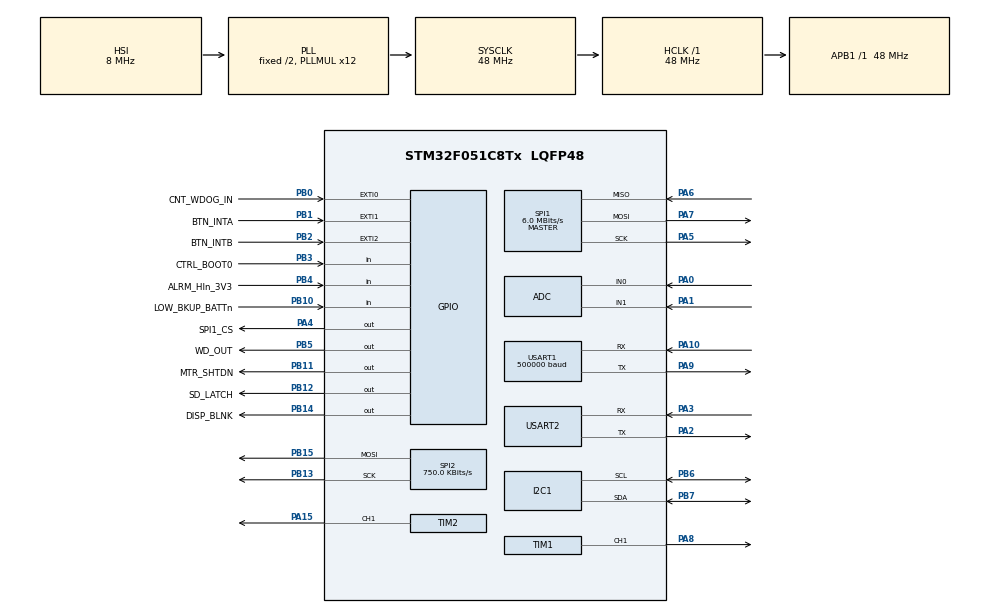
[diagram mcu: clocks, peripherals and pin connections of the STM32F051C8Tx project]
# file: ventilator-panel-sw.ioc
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Dma.Request0=USART1_RX
Dma.Request1=USART1_TX
Dma.USART1_RX.0.Direction=DMA_PERIPH_TO_MEMORY
Dma.USART1_RX.0.Instance=DMA1_Channel3
Dma.USART1_RX.0.MemDataAlignment=DMA_MDATAALIGN_BYTE
Dma.USART1_RX.0.MemInc=DMA_MINC_ENABLE
Dma.USART1_RX.0.Mode=DMA_CIRCULAR
Dma.USART1_RX.0.PeriphDataAlignment=DMA_PDATAALIGN_BYTE
Dma.USART1_RX.0.PeriphInc=DMA_PINC_DISABLE
Dma.USART1_RX.0.Priority=DMA_PRIORITY_VERY_HIGH
Dma.USART1_TX.1.Direction=DMA_MEMORY_TO_PERIPH
Dma.USART1_TX.1.Instance=DMA1_Channel2
Dma.USART1_TX.1.MemDataAlignment=DMA_MDATAALIGN_BYTE
Dma.USART1_TX.1.MemInc=DMA_MINC_ENABLE
Dma.USART1_TX.1.Mode=DMA_NORMAL
Dma.USART1_TX.1.PeriphDataAlignment=DMA_PDATAALIGN_BYTE
Dma.USART1_TX.1.PeriphInc=DMA_PINC_DISABLE
Dma.USART1_TX.1.Priority=DMA_PRIORITY_LOW
I2C1.Analog_Filter=I2C_ANALOGFILTER_ENABLE
I2C1.Timing=0x2000090E
Mcu.Family=STM32F0
Mcu.Name=STM32F051C8Tx
Mcu.Package=LQFP48
NVIC.DMA1_Channel2_3_IRQn=true\:0\:0\:false\:false\:true\:false\:true
NVIC.EXTI0_1_IRQn=true\:0\:0\:false\:false\:true\:true\:true
NVIC.TIM6_DAC_IRQn=true\:0\:0\:false\:false\:true\:true\:true
PA0.Mode=IN0
PA0.Signal=ADC_IN0
PA1.Mode=IN1
PA1.Signal=ADC_IN1
PA10.Mode=Asynchronous
PA10.Signal=USART1_RX
PA13.Mode=Serial_Wire
PA13.Signal=SYS_SWDIO
PA14.Mode=Serial_Wire
PA14.Signal=SYS_SWCLK
PA15.Signal=S_TIM2_CH1_ETR
PA2.Mode=Asynchronous
PA2.Signal=USART2_TX
PA3.Mode=Asynchronous
PA3.Signal=USART2_RX
PA4.GPIO_Label=SPI1_CS
PA4.Signal=GPIO_Output
PA5.Mode=Full_Duplex_Master
PA5.Signal=SPI1_SCK
PA6.Mode=Full_Duplex_Master
PA6.Signal=SPI1_MISO
PA7.Mode=Full_Duplex_Master
PA7.Signal=SPI1_MOSI
PA8.Signal=S_TIM1_CH1
PA9.Mode=Asynchronous
PA9.Signal=USART1_TX
PB0.GPIO_Label=CNT_WDOG_IN
PB0.GPIO_ModeDefaultEXTI=GPIO_MODE_IT_RISING_FALLING
PB0.Signal=GPXTI0
PB1.GPIO_Label=BTN_INTA
PB1.Signal=GPXTI1
PB10.GPIO_Label=LOW_BKUP_BATTn
PB10.Signal=GPIO_Input
PB11.GPIO_Label=MTR_SHTDN
PB11.Signal=GPIO_Output
PB12.GPIO_Label=SD_LATCH
PB12.Signal=GPIO_Output
PB13.Mode=TX_Only_Simplex_Unidirect_Master
PB13.Signal=SPI2_SCK
PB14.GPIO_Label=DISP_BLNK
PB14.PinState=GPIO_PIN_SET
PB14.Signal=GPIO_Output
PB15.Mode=TX_Only_Simplex_Unidirect_Master
PB15.Signal=SPI2_MOSI
PB2.GPIO_Label=BTN_INTB
PB2.Signal=GPXTI2
PB3.GPIO_Label=CTRL_BOOT0
PB3.Signal=GPIO_Input
PB4.GPIO_Label=ALRM_HIn_3V3
PB4.Signal=GPIO_Input
PB5.GPIO_Label=WD_OUT
PB5.Signal=GPIO_Output
PB6.Mode=I2C
PB6.Signal=I2C1_SCL
PB7.Mode=I2C
PB7.Signal=I2C1_SDA
ProjectManager.HeapSize=0x200
ProjectManager.StackSize=0x400
ProjectManager.TargetToolchain=STM32CubeIDE
RCC.AHBFreq_Value=48000000
RCC.APB1Freq_Value=48000000
RCC.APB1TimFreq_Value=48000000
RCC.HCLKFreq_Value=48000000
RCC.PLLMUL=RCC_PLL_MUL12
RCC.SYSCLKFreq_VALUE=48000000
RCC.SYSCLKSource=RCC_SYSCLKSOURCE_PLLCLK
SH.S_TIM1_CH1.0=TIM1_CH1,PWM Generation1 CH1
SH.S_TIM2_CH1_ETR.0=TIM2_CH1,PWM Generation1 CH1
SPI1.BaudRatePrescaler=SPI_BAUDRATEPRESCALER_8
SPI1.CLKPolarity=SPI_POLARITY_LOW
SPI1.CalculateBaudRate=6.0 MBits/s
SPI1.DataSize=SPI_DATASIZE_8BIT
SPI1.Direction=SPI_DIRECTION_2LINES
SPI1.Mode=SPI_MODE_MASTER
SPI1.VirtualType=VM_MASTER
SPI2.BaudRatePrescaler=SPI_BAUDRATEPRESCALER_64
SPI2.CalculateBaudRate=750.0 KBits/s
SPI2.DataSize=SPI_DATASIZE_16BIT
SPI2.Direction=SPI_DIRECTION_2LINES
SPI2.Mode=SPI_MODE_MASTER
SPI2.NSSPMode=SPI_NSS_PULSE_ENABLE
SPI2.VirtualType=VM_MASTER
TIM1.AutoReloadPreload=TIM_AUTORELOAD_PRELOAD_ENABLE
TIM1.Channel-PWM\ Generation1\ CH1=TIM_CHANNEL_1
TIM1.ClockDivision=TIM_CLOCKDIVISION_DIV1
TIM1.Period=17167
TIM1.Prescaler=4
TIM1.Pulse-PWM\ Generation1\ CH1=8584
TIM2.AutoReloadPreload=TIM_AUTORELOAD_PRELOAD_ENABLE
TIM2.Channel-PWM\ Generation1\ CH1=TIM_CHANNEL_1
TIM2.Period=24
TIM2.Prescaler=4
TIM2.Pulse-PWM\ Generation1\ CH1=12
TIM6.AutoReloadPreload=TIM_AUTORELOAD_PRELOAD_ENABLE
TIM6.Period=1000
TIM6.Prescaler=47999
USART1.BaudRate=500000
USART1.VirtualMode-Asynchronous=VM_ASYNC
USART2.VirtualMode-Asynchronous=VM_ASYNC
VP_TIM1_VS_ClockSourceINT.Mode=Internal
VP_TIM2_VS_ClockSourceINT.Mode=Internal
VP_TIM6_VS_ClockSourceINT.Mode=Enable_Timer
board=custom

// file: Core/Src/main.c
/* USER CODE BEGIN Header */
/**
  ******************************************************************************
  * @file           : main.c
  * @brief          : Main program body
  ******************************************************************************
  * @attention
  *
  * <h2><center>&copy; Copyright (c) 2020 STMicroelectronics.
  * All rights reserved.</center></h2>
  *
  * This software component is licensed by ST under BSD 3-Clause license,
  * the "License"; You may not use this file except in compliance with the
  * License. You may obtain a copy of the License at:
  *                        opensource.org/licenses/BSD-3-Clause
  *
  ******************************************************************************
  */
/* USER CODE END Header */

#include "main.h"

/* USER CODE BEGIN Includes */
#include <ventilator/cycle.h>
#include <ventilator/panel.h>
#include <ventilator/types.h>
#define EXTERN // Forces variables to be instantiated
#include <ventilator/panel_public.h>

/* USER CODE END Includes */

ADC_HandleTypeDef hadc;

I2C_HandleTypeDef hi2c1;

SPI_HandleTypeDef hspi1;
SPI_HandleTypeDef hspi2;

TIM_HandleTypeDef htim1;
TIM_HandleTypeDef htim2;
TIM_HandleTypeDef htim6;

UART_HandleTypeDef huart1;
UART_HandleTypeDef huart2;
DMA_HandleTypeDef hdma_usart1_rx;
DMA_HandleTypeDef hdma_usart1_tx;

/* USER CODE BEGIN PV */

// Instantiate public handles by undef'ing EXTERN

volatile FailSafeClockState p_doFail = FAIL_SAFE_CLOCK_UNINITIALIZED; // Needs to be set immediately

/* USER CODE END PV */

void SystemClock_Config(void);
static void MX_GPIO_Init(void);
static void MX_DMA_Init(void);
static void MX_ADC_Init(void);
static void MX_I2C1_Init(void);
static void MX_SPI1_Init(void);
static void MX_SPI2_Init(void);
static void MX_TIM1_Init(void);
static void MX_TIM2_Init(void);
static void MX_TIM6_Init(void);
static void MX_USART1_UART_Init(void);
static void MX_USART2_UART_Init(void);

int main(void)
{

  /* MCU Configuration--------------------------------------------------------*/

  /* Reset of all peripherals, Initializes the Flash interface and the Systick. */
  (void) HAL_Init();

  /* Configure the system clock */
  SystemClock_Config();

  /* Initialize all configured peripherals */
  MX_GPIO_Init();
  MX_DMA_Init();
  MX_ADC_Init();
  MX_I2C1_Init();
  MX_SPI1_Init();
  MX_SPI2_Init();
  MX_TIM1_Init();
  MX_TIM2_Init();
  MX_TIM6_Init();
  MX_USART1_UART_Init();
  MX_USART2_UART_Init();
  /* USER CODE BEGIN 2 */
  HAL_GPIO_WritePin(GPIOB, MTR_SHTDN_Pin, GPIO_PIN_RESET);  //Don't shutdown motor
  panel_init();
  /* USER CODE END 2 */

  /* Infinite loop */
  /* USER CODE BEGIN WHILE */
  //Start the 1Hz timer for debugging
  SW_ASSERT(HAL_TIM_Base_Start_IT(&htim6) == HAL_OK);
  p_doFail = FAIL_SAFE_CLOCK_RUNNING;  // Unleash the fail-safe clock
  while (1)
  {
    /* USER CODE END WHILE */

    /* USER CODE BEGIN 3 */
    cycle();
  }
  /* USER CODE END 3 */
}

void SystemClock_Config(void)
{
  RCC_OscInitTypeDef RCC_OscInitStruct = {0};
  RCC_ClkInitTypeDef RCC_ClkInitStruct = {0};
  RCC_PeriphCLKInitTypeDef PeriphClkInit = {0};

  /** Initializes the CPU, AHB and APB busses clocks
  */
  RCC_OscInitStruct.OscillatorType = RCC_OSCILLATORTYPE_HSI|RCC_OSCILLATORTYPE_HSI14;
  RCC_OscInitStruct.HSIState = RCC_HSI_ON;
  RCC_OscInitStruct.HSI14State = RCC_HSI14_ON;
  RCC_OscInitStruct.HSICalibrationValue = RCC_HSICALIBRATION_DEFAULT;
  RCC_OscInitStruct.HSI14CalibrationValue = 16;
  RCC_OscInitStruct.PLL.PLLState = RCC_PLL_ON;
  RCC_OscInitStruct.PLL.PLLSource = RCC_PLLSOURCE_HSI;
  RCC_OscInitStruct.PLL.PLLMUL = RCC_PLL_MUL12;
  RCC_OscInitStruct.PLL.PREDIV = RCC_PREDIV_DIV1;
  if (HAL_RCC_OscConfig(&RCC_OscInitStruct) != HAL_OK)
  {
    Error_Handler();
  }
  /** Initializes the CPU, AHB and APB busses clocks
  */
  RCC_ClkInitStruct.ClockType = RCC_CLOCKTYPE_HCLK|RCC_CLOCKTYPE_SYSCLK
                              |RCC_CLOCKTYPE_PCLK1;
  RCC_ClkInitStruct.SYSCLKSource = RCC_SYSCLKSOURCE_PLLCLK;
  RCC_ClkInitStruct.AHBCLKDivider = RCC_SYSCLK_DIV1;
  RCC_ClkInitStruct.APB1CLKDivider = RCC_HCLK_DIV1;

  if (HAL_RCC_ClockConfig(&RCC_ClkInitStruct, FLASH_LATENCY_1) != HAL_OK)
  {
    Error_Handler();
  }
  PeriphClkInit.PeriphClockSelection = RCC_PERIPHCLK_USART1|RCC_PERIPHCLK_I2C1;
  PeriphClkInit.Usart1ClockSelection = RCC_USART1CLKSOURCE_PCLK1;
  PeriphClkInit.I2c1ClockSelection = RCC_I2C1CLKSOURCE_HSI;
  if (HAL_RCCEx_PeriphCLKConfig(&PeriphClkInit) != HAL_OK)
  {
    Error_Handler();
  }
}

static void MX_ADC_Init(void)
{

  ADC_ChannelConfTypeDef sConfig = {0};

  /** Configure the global features of the ADC (Clock, Resolution, Data Alignment and number of conversion)
  */
  hadc.Instance = ADC1;
  hadc.Init.ClockPrescaler = ADC_CLOCK_ASYNC_DIV1;
  hadc.Init.Resolution = ADC_RESOLUTION_12B;
  hadc.Init.DataAlign = ADC_DATAALIGN_RIGHT;
  hadc.Init.ScanConvMode = ADC_SCAN_DIRECTION_FORWARD;
  hadc.Init.EOCSelection = ADC_EOC_SINGLE_CONV;
  hadc.Init.LowPowerAutoWait = DISABLE;
  hadc.Init.LowPowerAutoPowerOff = DISABLE;
  hadc.Init.ContinuousConvMode = DISABLE;
  hadc.Init.DiscontinuousConvMode = DISABLE;
  hadc.Init.ExternalTrigConv = ADC_SOFTWARE_START;
  hadc.Init.ExternalTrigConvEdge = ADC_EXTERNALTRIGCONVEDGE_NONE;
  hadc.Init.DMAContinuousRequests = DISABLE;
  hadc.Init.Overrun = ADC_OVR_DATA_PRESERVED;
  if (HAL_ADC_Init(&hadc) != HAL_OK)
  {
    Error_Handler();
  }
  /** Configure for the selected ADC regular channel to be converted.
  */
  sConfig.Channel = ADC_CHANNEL_0;
  sConfig.Rank = ADC_RANK_CHANNEL_NUMBER;
  sConfig.SamplingTime = ADC_SAMPLETIME_1CYCLE_5;
  if (HAL_ADC_ConfigChannel(&hadc, &sConfig) != HAL_OK)
  {
    Error_Handler();
  }
  /** Configure for the selected ADC regular channel to be converted.
  */
  sConfig.Channel = ADC_CHANNEL_1;
  if (HAL_ADC_ConfigChannel(&hadc, &sConfig) != HAL_OK)
  {
    Error_Handler();
  }

}

static void MX_I2C1_Init(void)
{

  hi2c1.Instance = I2C1;
  hi2c1.Init.Timing = 0x2000090E;
  hi2c1.Init.OwnAddress1 = 0;
  hi2c1.Init.AddressingMode = I2C_ADDRESSINGMODE_7BIT;
  hi2c1.Init.DualAddressMode = I2C_DUALADDRESS_DISABLE;
  hi2c1.Init.OwnAddress2 = 0;
  hi2c1.Init.OwnAddress2Masks = I2C_OA2_NOMASK;
  hi2c1.Init.GeneralCallMode = I2C_GENERALCALL_DISABLE;
  hi2c1.Init.NoStretchMode = I2C_NOSTRETCH_DISABLE;
  if (HAL_I2C_Init(&hi2c1) != HAL_OK)
  {
    Error_Handler();
  }
  /** Configure Analogue filter
  */
  if (HAL_I2CEx_ConfigAnalogFilter(&hi2c1, I2C_ANALOGFILTER_ENABLE) != HAL_OK)
  {
    Error_Handler();
  }
  /** Configure Digital filter
  */
  if (HAL_I2CEx_ConfigDigitalFilter(&hi2c1, 0) != HAL_OK)
  {
    Error_Handler();
  }

}

static void MX_SPI1_Init(void)
{

  /* SPI1 parameter configuration*/
  hspi1.Instance = SPI1;
  hspi1.Init.Mode = SPI_MODE_MASTER;
  hspi1.Init.Direction = SPI_DIRECTION_2LINES;
  hspi1.Init.DataSize = SPI_DATASIZE_8BIT;
  hspi1.Init.CLKPolarity = SPI_POLARITY_LOW;
  hspi1.Init.CLKPhase = SPI_PHASE_1EDGE;
  hspi1.Init.NSS = SPI_NSS_SOFT;
  hspi1.Init.BaudRatePrescaler = SPI_BAUDRATEPRESCALER_8;
  hspi1.Init.FirstBit = SPI_FIRSTBIT_MSB;
  hspi1.Init.TIMode = SPI_TIMODE_DISABLE;
  hspi1.Init.CRCCalculation = SPI_CRCCALCULATION_DISABLE;
  hspi1.Init.CRCPolynomial = 7;
  hspi1.Init.CRCLength = SPI_CRC_LENGTH_DATASIZE;
  hspi1.Init.NSSPMode = SPI_NSS_PULSE_ENABLE;
  if (HAL_SPI_Init(&hspi1) != HAL_OK)
  {
    Error_Handler();
  }

}

static void MX_SPI2_Init(void)
{

  /* SPI2 parameter configuration*/
  hspi2.Instance = SPI2;
  hspi2.Init.Mode = SPI_MODE_MASTER;
  hspi2.Init.Direction = SPI_DIRECTION_2LINES;
  hspi2.Init.DataSize = SPI_DATASIZE_16BIT;
  hspi2.Init.CLKPolarity = SPI_POLARITY_LOW;
  hspi2.Init.CLKPhase = SPI_PHASE_1EDGE;
  hspi2.Init.NSS = SPI_NSS_SOFT;
  hspi2.Init.BaudRatePrescaler = SPI_BAUDRATEPRESCALER_64;
  hspi2.Init.FirstBit = SPI_FIRSTBIT_MSB;
  hspi2.Init.TIMode = SPI_TIMODE_DISABLE;
  hspi2.Init.CRCCalculation = SPI_CRCCALCULATION_DISABLE;
  hspi2.Init.CRCPolynomial = 7;
  hspi2.Init.CRCLength = SPI_CRC_LENGTH_DATASIZE;
  hspi2.Init.NSSPMode = SPI_NSS_PULSE_ENABLE;
  if (HAL_SPI_Init(&hspi2) != HAL_OK)
  {
    Error_Handler();
  }

}

static void MX_TIM1_Init(void)
{

  TIM_ClockConfigTypeDef sClockSourceConfig = {0};
  TIM_MasterConfigTypeDef sMasterConfig = {0};
  TIM_OC_InitTypeDef sConfigOC = {0};
  TIM_BreakDeadTimeConfigTypeDef sBreakDeadTimeConfig = {0};

  htim1.Instance = TIM1;
  htim1.Init.Prescaler = 4;
  htim1.Init.CounterMode = TIM_COUNTERMODE_UP;
  htim1.Init.Period = 17167;
  htim1.Init.ClockDivision = TIM_CLOCKDIVISION_DIV1;
  htim1.Init.RepetitionCounter = 0;
  htim1.Init.AutoReloadPreload = TIM_AUTORELOAD_PRELOAD_ENABLE;
  if (HAL_TIM_Base_Init(&htim1) != HAL_OK)
  {
    Error_Handler();
  }
  sClockSourceConfig.ClockSource = TIM_CLOCKSOURCE_INTERNAL;
  if (HAL_TIM_ConfigClockSource(&htim1, &sClockSourceConfig) != HAL_OK)
  {
    Error_Handler();
  }
  if (HAL_TIM_PWM_Init(&htim1) != HAL_OK)
  {
    Error_Handler();
  }
  sMasterConfig.MasterOutputTrigger = TIM_TRGO_RESET;
  sMasterConfig.MasterSlaveMode = TIM_MASTERSLAVEMODE_DISABLE;
  if (HAL_TIMEx_MasterConfigSynchronization(&htim1, &sMasterConfig) != HAL_OK)
  {
    Error_Handler();
  }
  sConfigOC.OCMode = TIM_OCMODE_PWM1;
  sConfigOC.Pulse = 8584;
  sConfigOC.OCPolarity = TIM_OCPOLARITY_HIGH;
  sConfigOC.OCNPolarity = TIM_OCNPOLARITY_HIGH;
  sConfigOC.OCFastMode = TIM_OCFAST_DISABLE;
  sConfigOC.OCIdleState = TIM_OCIDLESTATE_RESET;
  sConfigOC.OCNIdleState = TIM_OCNIDLESTATE_RESET;
  if (HAL_TIM_PWM_ConfigChannel(&htim1, &sConfigOC, TIM_CHANNEL_1) != HAL_OK)
  {
    Error_Handler();
  }
  sBreakDeadTimeConfig.OffStateRunMode = TIM_OSSR_DISABLE;
  sBreakDeadTimeConfig.OffStateIDLEMode = TIM_OSSI_DISABLE;
  sBreakDeadTimeConfig.LockLevel = TIM_LOCKLEVEL_OFF;
  sBreakDeadTimeConfig.DeadTime = 0;
  sBreakDeadTimeConfig.BreakState = TIM_BREAK_DISABLE;
  sBreakDeadTimeConfig.BreakPolarity = TIM_BREAKPOLARITY_HIGH;
  sBreakDeadTimeConfig.AutomaticOutput = TIM_AUTOMATICOUTPUT_DISABLE;
  if (HAL_TIMEx_ConfigBreakDeadTime(&htim1, &sBreakDeadTimeConfig) != HAL_OK)
  {
    Error_Handler();
  }
  HAL_TIM_MspPostInit(&htim1);

}

static void MX_TIM2_Init(void)
{

  TIM_ClockConfigTypeDef sClockSourceConfig = {0};
  TIM_MasterConfigTypeDef sMasterConfig = {0};
  TIM_OC_InitTypeDef sConfigOC = {0};

  htim2.Instance = TIM2;
  htim2.Init.Prescaler = 4;
  htim2.Init.CounterMode = TIM_COUNTERMODE_UP;
  htim2.Init.Period = 24;
  htim2.Init.ClockDivision = TIM_CLOCKDIVISION_DIV1;
  htim2.Init.AutoReloadPreload = TIM_AUTORELOAD_PRELOAD_ENABLE;
  if (HAL_TIM_Base_Init(&htim2) != HAL_OK)
  {
    Error_Handler();
  }
  sClockSourceConfig.ClockSource = TIM_CLOCKSOURCE_INTERNAL;
  if (HAL_TIM_ConfigClockSource(&htim2, &sClockSourceConfig) != HAL_OK)
  {
    Error_Handler();
  }
  if (HAL_TIM_PWM_Init(&htim2) != HAL_OK)
  {
    Error_Handler();
  }
  sMasterConfig.MasterOutputTrigger = TIM_TRGO_RESET;
  sMasterConfig.MasterSlaveMode = TIM_MASTERSLAVEMODE_DISABLE;
  if (HAL_TIMEx_MasterConfigSynchronization(&htim2, &sMasterConfig) != HAL_OK)
  {
    Error_Handler();
  }
  sConfigOC.OCMode = TIM_OCMODE_PWM1;
  sConfigOC.Pulse = 12;
  sConfigOC.OCPolarity = TIM_OCPOLARITY_HIGH;
  sConfigOC.OCFastMode = TIM_OCFAST_DISABLE;
  if (HAL_TIM_PWM_ConfigChannel(&htim2, &sConfigOC, TIM_CHANNEL_1) != HAL_OK)
  {
    Error_Handler();
  }
  HAL_TIM_MspPostInit(&htim2);

}

static void MX_TIM6_Init(void)
{

  TIM_MasterConfigTypeDef sMasterConfig = {0};

  htim6.Instance = TIM6;
  htim6.Init.Prescaler = 47999;
  htim6.Init.CounterMode = TIM_COUNTERMODE_UP;
  htim6.Init.Period = 1000;
  htim6.Init.AutoReloadPreload = TIM_AUTORELOAD_PRELOAD_ENABLE;
  if (HAL_TIM_Base_Init(&htim6) != HAL_OK)
  {
    Error_Handler();
  }
  sMasterConfig.MasterOutputTrigger = TIM_TRGO_RESET;
  sMasterConfig.MasterSlaveMode = TIM_MASTERSLAVEMODE_DISABLE;
  if (HAL_TIMEx_MasterConfigSynchronization(&htim6, &sMasterConfig) != HAL_OK)
  {
    Error_Handler();
  }

}

static void MX_USART1_UART_Init(void)
{

  huart1.Instance = USART1;
  huart1.Init.BaudRate = 500000;
  huart1.Init.WordLength = UART_WORDLENGTH_8B;
  huart1.Init.StopBits = UART_STOPBITS_1;
  huart1.Init.Parity = UART_PARITY_NONE;
  huart1.Init.Mode = UART_MODE_TX_RX;
  huart1.Init.HwFlowCtl = UART_HWCONTROL_NONE;
  huart1.Init.OverSampling = UART_OVERSAMPLING_16;
  huart1.Init.OneBitSampling = UART_ONE_BIT_SAMPLE_DISABLE;
  huart1.AdvancedInit.AdvFeatureInit = UART_ADVFEATURE_NO_INIT;
  if (HAL_UART_Init(&huart1) != HAL_OK)
  {
    Error_Handler();
  }

}

static void MX_USART2_UART_Init(void)
{

  huart2.Instance = USART2;
  huart2.Init.BaudRate = 38400;
  huart2.Init.WordLength = UART_WORDLENGTH_8B;
  huart2.Init.StopBits = UART_STOPBITS_1;
  huart2.Init.Parity = UART_PARITY_NONE;
  huart2.Init.Mode = UART_MODE_TX_RX;
  huart2.Init.HwFlowCtl = UART_HWCONTROL_NONE;
  huart2.Init.OverSampling = UART_OVERSAMPLING_16;
  huart2.Init.OneBitSampling = UART_ONE_BIT_SAMPLE_DISABLE;
  huart2.AdvancedInit.AdvFeatureInit = UART_ADVFEATURE_NO_INIT;
  if (HAL_UART_Init(&huart2) != HAL_OK)
  {
    Error_Handler();
  }

}

static void MX_DMA_Init(void)
{

  /* DMA controller clock enable */
  __HAL_RCC_DMA1_CLK_ENABLE();

  /* DMA interrupt init */
  /* DMA1_Channel2_3_IRQn interrupt configuration */
  HAL_NVIC_SetPriority(DMA1_Channel2_3_IRQn, 0, 0);
  HAL_NVIC_EnableIRQ(DMA1_Channel2_3_IRQn);

}

static void MX_GPIO_Init(void)
{
  GPIO_InitTypeDef GPIO_InitStruct = {0};

  /* GPIO Ports Clock Enable */
  __HAL_RCC_GPIOA_CLK_ENABLE();
  __HAL_RCC_GPIOB_CLK_ENABLE();

  /*Configure GPIO pin Output Level */
  HAL_GPIO_WritePin(SPI1_CS_GPIO_Port, SPI1_CS_Pin, GPIO_PIN_RESET);

  /*Configure GPIO pin Output Level */
  HAL_GPIO_WritePin(GPIOB, MTR_SHTDN_Pin|SD_LATCH_Pin|WD_OUT_Pin, GPIO_PIN_RESET);

  /*Configure GPIO pin Output Level */
  HAL_GPIO_WritePin(DISP_BLNK_GPIO_Port, DISP_BLNK_Pin, GPIO_PIN_SET);

  /*Configure GPIO pin : SPI1_CS_Pin */
  GPIO_InitStruct.Pin = SPI1_CS_Pin;
  GPIO_InitStruct.Mode = GPIO_MODE_OUTPUT_PP;
  GPIO_InitStruct.Pull = GPIO_NOPULL;
  GPIO_InitStruct.Speed = GPIO_SPEED_FREQ_LOW;
  HAL_GPIO_Init(SPI1_CS_GPIO_Port, &GPIO_InitStruct);

  /*Configure GPIO pin : CNT_WDOG_IN_Pin */
  GPIO_InitStruct.Pin = CNT_WDOG_IN_Pin;
  GPIO_InitStruct.Mode = GPIO_MODE_IT_RISING_FALLING;
  GPIO_InitStruct.Pull = GPIO_NOPULL;
  HAL_GPIO_Init(CNT_WDOG_IN_GPIO_Port, &GPIO_InitStruct);

  /*Configure GPIO pins : BTN_INTA_Pin BTN_INTB_Pin */
  GPIO_InitStruct.Pin = BTN_INTA_Pin|BTN_INTB_Pin;
  GPIO_InitStruct.Mode = GPIO_MODE_IT_RISING;
  GPIO_InitStruct.Pull = GPIO_NOPULL;
  HAL_GPIO_Init(GPIOB, &GPIO_InitStruct);

  /*Configure GPIO pins : LOW_BKUP_BATTn_Pin CTRL_BOOT0_Pin ALRM_HIn_3V3_Pin */
  GPIO_InitStruct.Pin = LOW_BKUP_BATTn_Pin|CTRL_BOOT0_Pin|ALRM_HIn_3V3_Pin;
  GPIO_InitStruct.Mode = GPIO_MODE_INPUT;
  GPIO_InitStruct.Pull = GPIO_NOPULL;
  HAL_GPIO_Init(GPIOB, &GPIO_InitStruct);

  /*Configure GPIO pins : MTR_SHTDN_Pin SD_LATCH_Pin DISP_BLNK_Pin WD_OUT_Pin */
  GPIO_InitStruct.Pin = MTR_SHTDN_Pin|SD_LATCH_Pin|DISP_BLNK_Pin|WD_OUT_Pin;
  GPIO_InitStruct.Mode = GPIO_MODE_OUTPUT_PP;
  GPIO_InitStruct.Pull = GPIO_NOPULL;
  GPIO_InitStruct.Speed = GPIO_SPEED_FREQ_LOW;
  HAL_GPIO_Init(GPIOB, &GPIO_InitStruct);

  /* EXTI interrupt init*/
  HAL_NVIC_SetPriority(EXTI0_1_IRQn, 0, 0);
  HAL_NVIC_EnableIRQ(EXTI0_1_IRQn);

}

/* USER CODE BEGIN 4 */

// Handle controller watchdog discrete interrupt here
void HAL_GPIO_EXTI_Callback(uint16_t GPIO_Pin)
{
    if (GPIO_PIN_0 == GPIO_Pin) {
        p_doCycle = 1; // set flag for waiting loop
    }
}

/* USER CODE END 4 */

void Error_Handler(void)
{
}

/************************ (C) COPYRIGHT STMicroelectronics *****END OF FILE****/
